# STM32F0x2 register map
File version: 1.3
CPU: CM0 r0p0, little endian, no MPU, no FPU, 2 interrupt priority bits
Registers are 32-bit, read-write, reset 0x0 unless marked. A register's access mark holds for its fields unless they carry their own. Offsets are from the block's base; lines under a group give offsets from that group; [hi:lo] are bit positions; {n}, {i} and the like mark numbered series; 'fields as' and 'values as' point back to an identical list; <NAME> marks a mode.

## Memory map
0x40000000 TIM2 size 0x400 — General-purpose-timers
0x40000400 TIM3 size 0x400 — General-purpose-timers
0x40001000 TIM6 size 0x400 — Basic-timers
0x40001400 TIM7 size 0x400
0x40002000 TIM14 size 0x400 — General-purpose-timers
0x40002800 RTC size 0x400 — Real-time clock
0x40002C00 WWDG size 0x400 — Window watchdog
0x40003000 IWDG size 0x400 — Independent watchdog
0x40003800 SPI2 size 0x400
0x40004400 USART2 size 0x400
0x40004800 USART3 size 0x400
0x40004C00 USART4 size 0x400
0x40005400 I2C1 size 0x400 — Inter-integrated circuit
0x40005800 I2C2 size 0x400
0x40005C00 USB size 0x400 — Universal serial bus full-speed device interface
0x40006400 CAN size 0x400 — Controller area network
0x40006C00 CRS size 0x400 — Clock recovery system
0x40007000 PWR size 0x400 — Power control
0x40007400 DAC size 0x400 — Digital-to-analog converter
0x40007800 CEC size 0x400 — HDMI-CEC controller
0x40010000 SYSCFG size 0x21 — System configuration controller
0x40010000 COMP size 0x400 — General purpose comparators
0x40010400 EXTI size 0x400 — External interrupt/event controller
0x40012400 ADC size 0x400 — Analog-to-digital converter
0x40012C00 TIM1 size 0x400 — Advanced-timers
0x40013000 SPI1 size 0x400 — Serial peripheral interface
0x40013800 USART1 size 0x400 — Universal synchronous asynchronous receiver transmitter
0x40014000 TIM15 size 0x400 — General-purpose-timers
0x40014400 TIM16 size 0x400 — General-purpose-timers
0x40014800 TIM17 size 0x400
0x40015800 DBGMCU size 0x400 — Debug support
0x40020000 DMA1 size 0x400 — DMA controller
0x40021000 RCC size 0x400 — Reset and clock control
0x40022000 Flash size 0x400
0x40023000 CRC size 0x400 — cyclic redundancy check calculation unit
0x40024000 TSC size 0x400 — Touch sensing controller
0x48000000 GPIOA size 0x400 — General-purpose I/Os
0x48000400 GPIOB size 0x400
0x48000800 GPIOC size 0x400
0x48000C00 GPIOD size 0x400
0x48001000 GPIOE size 0x400
0x48001400 GPIOF size 0x400 — General-purpose I/Os
0xE000E010 STK size 0x11 — SysTick timer
0xE000E100 NVIC size 0x33D — Nested Vectored Interrupt Controller
0xE000ED00 SCB size 0x41 — System control block

## Interrupts
0 WWDG — Window Watchdog interrupt
1 PVD (EXTI) — PVD and VDDIO2 supply comparator interrupt
2 RTC — RTC interrupts
3 FLASH (Flash) — Flash global interrupt
4 RCC_CRS (RCC) — RCC and CRS global interrupts
5 EXTI0_1 (EXTI) — EXTI Line[1:0] interrupts
6 EXTI2_3 (EXTI) — EXTI Line[3:2] interrupts
7 EXTI4_15 (EXTI) — EXTI Line15 and EXTI4 interrupts
8 TSC — Touch sensing interrupt
9 DMA1_CH1 (DMA1) — DMA1 channel 1 interrupt
10 DMA1_CH2_3 (DMA1) — DMA channel 2 and 3 interrupts
11 DMA1_CH4_5_6_7 (DMA1) — DMA channel 4, 5, 6 and 7 interrupts
12 ADC_COMP (ADC) — ADC and comparator interrupts
13 TIM1_BRK_UP_TRG_COM (TIM1) — TIM1 break, update, trigger and commutation interrupt
14 TIM1_CC (TIM1) — TIM1 Capture Compare interrupt
15 TIM2 — TIM2 global interrupt
16 TIM3 — TIM3 global interrupt
17 TIM6_DAC (DAC) — TIM6 global interrupt and DAC underrun interrupt
18 TIM7 — TIM7 global interrupt
19 TIM14 — TIM14 global interrupt
20 TIM15 — TIM15 global interrupt
21 TIM16 — TIM16 global interrupt
22 TIM17 — TIM17 global interrupt
23 I2C1 — I2C1 global interrupt
24 I2C2 — I2C2 global interrupt
25 SPI1 — SPI1_global_interrupt
26 SPI2 — SPI2 global interrupt
27 USART1 — USART1 global interrupt
28 USART2 — USART2 global interrupt
29 USART3_4 (USART3) — USART3 and USART4 global interrupt
30 CEC_CAN (CEC) — CEC and CAN global interrupt
31 USB — USB global interrupt

## CRC — cyclic redundancy check calculation unit
Base 0x40023000
0x00 DR reset 0xFFFFFFFF — Data register
  [31:0] DR — Data register bits
0x00 DR8 8-bit reset 0xFF (alternate view of DR) — Data register - byte sized
  [7:0] DR8 — Data register bits
0x00 DR16 16-bit reset 0xFFFF (alternate view of DR) — Data register - half-word sized
  [15:0] DR16 — Data register bits
0x04 IDR — Independent data register
  [7:0] IDR — General-purpose 8-bit data register bits
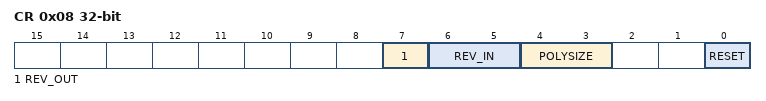
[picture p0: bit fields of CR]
0x08 CR — Control register
  [7] REV_OUT — Reverse output data
    0=Normal (Bit order not affected); 1=Reversed (Bit reversed output)
  [6:5] REV_IN — Reverse input data
    0=Normal (Bit order not affected); 1=Byte (Bit reversal done by byte); 2=HalfWord (Bit reversal done by half-word); 3=Word (Bit reversal done by word)
  [4:3] POLYSIZE — Polynomial size
    0=32-bit polynomial; 1=16-bit polynomial; 2=8-bit polynomial; 3=7-bit polynomial
  [0] RESET — reset bit
    on write: 1=Resets the CRC calculation unit and sets the data register to 0xFFFF FFFF
0x10 INIT reset 0xFFFFFFFF — Initial CRC value
  [31:0] INIT — Programmable initial CRC value
0x14 POL reset 0x4C11DB7 — CRC polynomial
  [31:0] POL — Programmable polynomial
